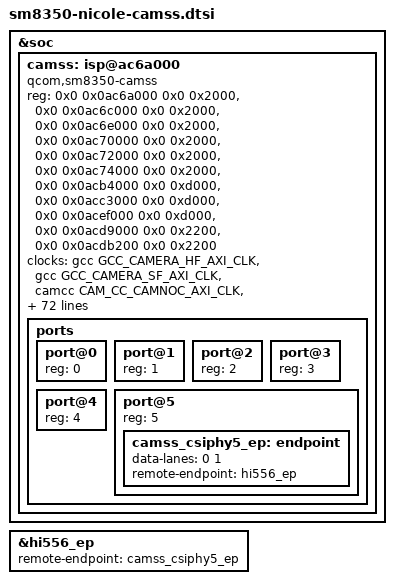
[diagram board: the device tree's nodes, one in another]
// SPDX-License-Identifier: GPL-2.0-only
/*
 * SM8350 CAMSS node for the Razer Edge (nicole), stage 2 of the front
 * camera (6 Kasım 2026, first used in kernel r22). Needs the kernel patches
 * drivers/camera/0003-media-qcom-camss-add-SM8350-support.patch and
 * drivers/camera/0004-dt-bindings-media-add-qcom-sm8350-camss.patch.
 *
 * Included at the very end of
 * sm8350-razer-nicole.dts (it needs the camcc, hi556_ep, pm8350_l5 and
 * pm8350_l6 labels defined there). The first part is what would go into
 * sm8350.dtsi upstream (status = "disabled"), the second part is the board
 * part.
 *
 * Sources: Razer downstream camera/lahaina-camera.dtsi (csiphy0-5, csid0-2,
 * ife0-2, csid-lite0/1, ife-lite0/1, qcom,cam-cpas, qcom,cam_smmu) and
 * camera/lahaina-camera-sensor-nicole.dtsi (csiphy-sd-index = 5).
 * Anything marked GUESS is not taken from a Razer/Qualcomm source.
 */

&soc {
	camss: isp@ac6a000 {
		compatible = "qcom,sm8350-camss";

		/*
		 * CSIPHY sizes as downstream (0x2000 each). VFE regions as
		 * downstream "ife"/"ife-lite" regs; they contain the CSIDs
		 * (CSIDn = IFEn + 0x1200, CSID-lite = IFE-lite + 0x200, same
		 * layout as SM8250/Titan 480), so no separate csid regs.
		 */
		reg = <0x0 0x0ac6a000 0x0 0x2000>,
		      <0x0 0x0ac6c000 0x0 0x2000>,
		      <0x0 0x0ac6e000 0x0 0x2000>,
		      <0x0 0x0ac70000 0x0 0x2000>,
		      <0x0 0x0ac72000 0x0 0x2000>,
		      <0x0 0x0ac74000 0x0 0x2000>,
		      <0x0 0x0acb4000 0x0 0xd000>,
		      <0x0 0x0acc3000 0x0 0xd000>,
		      <0x0 0x0acef000 0x0 0xd000>,
		      <0x0 0x0acd9000 0x0 0x2200>,
		      <0x0 0x0acdb200 0x0 0x2200>;
		reg-names = "csiphy0",
			    "csiphy1",
			    "csiphy2",
			    "csiphy3",
			    "csiphy4",
			    "csiphy5",
			    "vfe0",
			    "vfe1",
			    "vfe2",
			    "vfe_lite0",
			    "vfe_lite1";

		/*
		 * GCC_CAMERA_AHB_CLK is not listed: mainline gcc-sm8350 keeps it
		 * always on and does not export it.
		 */
		clocks = <&gcc GCC_CAMERA_HF_AXI_CLK>,
			 <&gcc GCC_CAMERA_SF_AXI_CLK>,
			 <&camcc CAM_CC_CAMNOC_AXI_CLK>,
			 <&camcc CAM_CC_CAMNOC_AXI_CLK_SRC>,
			 <&camcc CAM_CC_CORE_AHB_CLK>,
			 <&camcc CAM_CC_CPAS_AHB_CLK>,
			 <&camcc CAM_CC_CSIPHY0_CLK>,
			 <&camcc CAM_CC_CSI0PHYTIMER_CLK>,
			 <&camcc CAM_CC_CSIPHY1_CLK>,
			 <&camcc CAM_CC_CSI1PHYTIMER_CLK>,
			 <&camcc CAM_CC_CSIPHY2_CLK>,
			 <&camcc CAM_CC_CSI2PHYTIMER_CLK>,
			 <&camcc CAM_CC_CSIPHY3_CLK>,
			 <&camcc CAM_CC_CSI3PHYTIMER_CLK>,
			 <&camcc CAM_CC_CSIPHY4_CLK>,
			 <&camcc CAM_CC_CSI4PHYTIMER_CLK>,
			 <&camcc CAM_CC_CSIPHY5_CLK>,
			 <&camcc CAM_CC_CSI5PHYTIMER_CLK>,
			 <&camcc CAM_CC_SLOW_AHB_CLK_SRC>,
			 <&camcc CAM_CC_IFE_0_AHB_CLK>,
			 <&camcc CAM_CC_IFE_0_AXI_CLK>,
			 <&camcc CAM_CC_IFE_0_CLK>,
			 <&camcc CAM_CC_IFE_0_CPHY_RX_CLK>,
			 <&camcc CAM_CC_IFE_0_CSID_CLK>,
			 <&camcc CAM_CC_IFE_0_AREG_CLK>,
			 <&camcc CAM_CC_IFE_1_AHB_CLK>,
			 <&camcc CAM_CC_IFE_1_AXI_CLK>,
			 <&camcc CAM_CC_IFE_1_CLK>,
			 <&camcc CAM_CC_IFE_1_CPHY_RX_CLK>,
			 <&camcc CAM_CC_IFE_1_CSID_CLK>,
			 <&camcc CAM_CC_IFE_1_AREG_CLK>,
			 <&camcc CAM_CC_IFE_2_AHB_CLK>,
			 <&camcc CAM_CC_IFE_2_AXI_CLK>,
			 <&camcc CAM_CC_IFE_2_CLK>,
			 <&camcc CAM_CC_IFE_2_CPHY_RX_CLK>,
			 <&camcc CAM_CC_IFE_2_CSID_CLK>,
			 <&camcc CAM_CC_IFE_2_AREG_CLK>,
			 <&camcc CAM_CC_IFE_LITE_AHB_CLK>,
			 <&camcc CAM_CC_IFE_LITE_AXI_CLK>,
			 <&camcc CAM_CC_IFE_LITE_CLK>,
			 <&camcc CAM_CC_IFE_LITE_CPHY_RX_CLK>,
			 <&camcc CAM_CC_IFE_LITE_CSID_CLK>;
		clock-names = "cam_hf_axi",
			      "cam_sf_axi",
			      "camnoc_axi",
			      "camnoc_axi_src",
			      "core_ahb",
			      "cpas_ahb",
			      "csiphy0",
			      "csiphy0_timer",
			      "csiphy1",
			      "csiphy1_timer",
			      "csiphy2",
			      "csiphy2_timer",
			      "csiphy3",
			      "csiphy3_timer",
			      "csiphy4",
			      "csiphy4_timer",
			      "csiphy5",
			      "csiphy5_timer",
			      "slow_ahb_src",
			      "vfe0_ahb",
			      "vfe0_axi",
			      "vfe0",
			      "vfe0_cphy_rx",
			      "vfe0_csid",
			      "vfe0_areg",
			      "vfe1_ahb",
			      "vfe1_axi",
			      "vfe1",
			      "vfe1_cphy_rx",
			      "vfe1_csid",
			      "vfe1_areg",
			      "vfe2_ahb",
			      "vfe2_axi",
			      "vfe2",
			      "vfe2_cphy_rx",
			      "vfe2_csid",
			      "vfe2_areg",
			      "vfe_lite_ahb",
			      "vfe_lite_axi",
			      "vfe_lite",
			      "vfe_lite_cphy_rx",
			      "vfe_lite_csid";

		interrupts = <GIC_SPI 477 IRQ_TYPE_EDGE_RISING>,
			     <GIC_SPI 478 IRQ_TYPE_EDGE_RISING>,
			     <GIC_SPI 479 IRQ_TYPE_EDGE_RISING>,
			     <GIC_SPI 448 IRQ_TYPE_EDGE_RISING>,
			     <GIC_SPI 122 IRQ_TYPE_EDGE_RISING>,
			     <GIC_SPI 89 IRQ_TYPE_EDGE_RISING>,
			     <GIC_SPI 464 IRQ_TYPE_EDGE_RISING>,
			     <GIC_SPI 466 IRQ_TYPE_EDGE_RISING>,
			     <GIC_SPI 640 IRQ_TYPE_EDGE_RISING>,
			     <GIC_SPI 468 IRQ_TYPE_EDGE_RISING>,
			     <GIC_SPI 359 IRQ_TYPE_EDGE_RISING>,
			     <GIC_SPI 465 IRQ_TYPE_EDGE_RISING>,
			     <GIC_SPI 467 IRQ_TYPE_EDGE_RISING>,
			     <GIC_SPI 641 IRQ_TYPE_EDGE_RISING>,
			     <GIC_SPI 469 IRQ_TYPE_EDGE_RISING>,
			     <GIC_SPI 360 IRQ_TYPE_EDGE_RISING>;
		interrupt-names = "csiphy0",
				  "csiphy1",
				  "csiphy2",
				  "csiphy3",
				  "csiphy4",
				  "csiphy5",
				  "csid0",
				  "csid1",
				  "csid2",
				  "csid_lite0",
				  "csid_lite1",
				  "vfe0",
				  "vfe1",
				  "vfe2",
				  "vfe_lite0",
				  "vfe_lite1";

		/*
		 * Paths from the downstream cpas node: cam_ahb (APPSS ->
		 * CAMERA_CFG), cam_hf_0, cam_sf_0, cam_sf_icp (CAMNOC -> EBI1).
		 * The tags follow the iris node in sm8350.dtsi (GUESS).
		 */
		interconnects = <&gem_noc MASTER_APPSS_PROC QCOM_ICC_TAG_ACTIVE_ONLY
				 &config_noc SLAVE_CAMERA_CFG QCOM_ICC_TAG_ACTIVE_ONLY>,
				<&mmss_noc MASTER_CAMNOC_HF QCOM_ICC_TAG_ALWAYS
				 &mc_virt SLAVE_EBI1 QCOM_ICC_TAG_ALWAYS>,
				<&mmss_noc MASTER_CAMNOC_SF QCOM_ICC_TAG_ALWAYS
				 &mc_virt SLAVE_EBI1 QCOM_ICC_TAG_ALWAYS>,
				<&mmss_noc MASTER_CAMNOC_ICP QCOM_ICC_TAG_ALWAYS
				 &mc_virt SLAVE_EBI1 QCOM_ICC_TAG_ALWAYS>;
		interconnect-names = "ahb",
				     "hf_mnoc",
				     "sf_mnoc",
				     "sf_icp_mnoc";

		/*
		 * As downstream msm_cam_smmu_ife ("ife", "ife-cdm"). With mask 0x440
		 * the four entries collapse into one SMR: 0x800, 0x840, 0xc00, 0xc40.
		 * The hypervisor only lets HLOS install the stream match it expects:
		 * the sm8250-style list (0x800/0x801/0x840/0x841 ... mask 0x400) left
		 * the four SMRs invalid while their S2CRs pointed at the context bank,
		 * so the first VFE write was an unmatched stream and the SoC reset
		 * (6 Kasım). 0x84400800 written by hand into SMR13 fixed it.
		 */
		iommus = <&apps_smmu 0x800 0x440>,
			 <&apps_smmu 0x840 0x440>,
			 <&apps_smmu 0xc00 0x440>,
			 <&apps_smmu 0xc40 0x440>;

		power-domains = <&camcc IFE_0_GDSC>,
				<&camcc IFE_1_GDSC>,
				<&camcc IFE_2_GDSC>,
				<&camcc TITAN_TOP_GDSC>;
		power-domain-names = "ife0",
				     "ife1",
				     "ife2",
				     "top";

		status = "disabled";

		ports {
			#address-cells = <1>;
			#size-cells = <0>;

			port@0 {
				reg = <0>;
			};

			port@1 {
				reg = <1>;
			};

			port@2 {
				reg = <2>;
			};

			port@3 {
				reg = <3>;
			};

			port@4 {
				reg = <4>;
			};

			port@5 {
				reg = <5>;
			};
		};
	};
};

/* ---- board part (sm8350-razer-nicole.dts) ---- */

&camss {
	/*
	 * Downstream csiphy0-5: csi-vdd-0p9 = pm8350_l5 (0.88 V, 96.4 mA),
	 * csi-vdd-1p2 = pm8350_l6 (1.2 V, 54 mA). Both rails are already on
	 * (fixed HPM) for the USB/UFS/DSI PHYs in our DTS.
	 */
	vdda-phy-supply = <&pm8350_l5>;
	vdda-pll-supply = <&pm8350_l6>;

	status = "okay";

	ports {
		/* Hi-556 front camera, csiphy-sd-index = 5 downstream */
		port@5 {
			camss_csiphy5_ep: endpoint {
				/*
				 * GUESS: the sensor uses PHY data lanes 0 and 1.
				 * The downstream nicole sensor dtsi gives only the
				 * PHY index, no lane map. D-PHY is the default bus
				 * type; clock-lanes is not used by CAMSS gen2 PHYs.
				 */
				data-lanes = <0 1>;
				remote-endpoint = <&hi556_ep>;
			};
		};
	};
};

&hi556_ep {
	remote-endpoint = <&camss_csiphy5_ep>;
};
